AUTOSAR XML (schema 00049)
package /SwComponentTypes
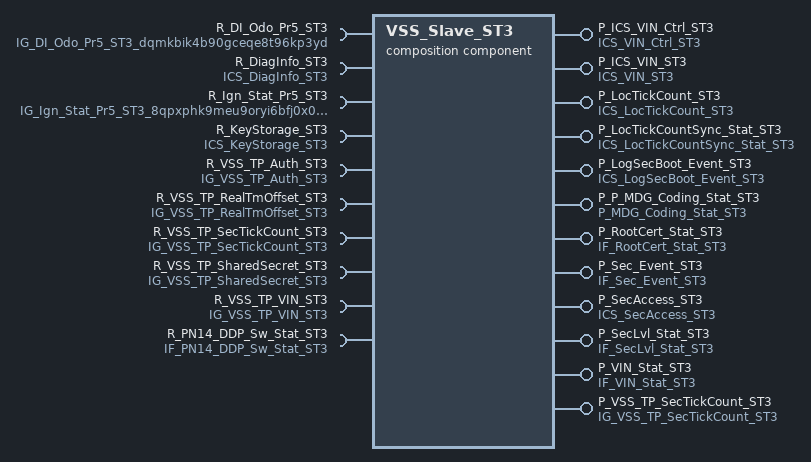
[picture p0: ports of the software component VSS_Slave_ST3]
  composition sw component type VSS_Slave_ST3  # Vehicle Security Slave
    11 x provide port:
      P_ICS_VIN_Ctrl_ST3: provided-com-specs=[{operation=Lock, queue-length=1}, {operation=Set, queue-length=1}], provided-interface=ICS_VIN_Ctrl_ST3  # Steuerung Fahrzeugidentifikationsnummer / Vehicle Identification Number control
      P_ICS_VIN_ST3: server-com-spec{operation=Get, queue-length=1}, provided-interface=ICS_VIN_ST3  # Fahrzeugidentifikationsnummer / Vehicle Identification Number
      P_LocTickCount_ST3: server-com-spec{operation=Get, queue-length=1}, provided-interface=ICS_LocTickCount_ST3  # Lokale Zeit / Local tick count
      P_LocTickCountSync_Stat_ST3: server-com-spec{operation=Get, queue-length=1}, provided-interface=ICS_LocTickCountSync_Stat_ST3  # Synchronisations-Status lokale Zeit / Local tick count synchronisation state
      P_LogSecBoot_Event_ST3: server-com-spec{operation=LogSecBootEvent, queue-length=1}, provided-interface=ICS_LogSecBoot_Event_ST3  # Security Boot-Ereignis aufzeichnen / Log security boot event
      P_P_MDG_Coding_Stat_ST3: mode-switch-sender-com-spec{mode-group=Coding_Status, queue-length=1}, provided-interface=P_MDG_Coding_Stat_ST3  # Kodierungs-Status / Coding state
      P_RootCert_Stat_ST3: nonqueued-sender-com-spec{data-element=isProductive, init-value=constant-reference=XDIS_h5tcyk98kzbgrc5svasomeyt}, provided-interface=IF_RootCert_Stat_ST3  # Status Root Certificate / Root certificate state
      P_Sec_Event_ST3: nonqueued-sender-com-spec{data-element=Data, init-value=constant-reference=XDIS_6146w3b2vgdunnu49c413rpbf}, provided-interface=IF_Sec_Event_ST3  # Security-Ereignis / Security event
      P_SecAccess_ST3: provided-com-specs=[{operation=CompareKey, queue-length=1}, {operation=GetSeed, queue-length=1}], provided-interface=ICS_SecAccess_ST3  # Security-Zugriff / Security access
      P_SecLvl_Stat_ST3: nonqueued-sender-com-spec{data-element=currentLevel, init-value=constant-reference=XDIS_2kt9ss9xytkqyzr4359iyexvi}, provided-interface=IF_SecLvl_Stat_ST3  # Status Security-Level / Security level state
      P_VIN_Stat_ST3: nonqueued-sender-com-spec{data-element=status, init-value=constant-reference=XDIS_e2iocagv39mx6wej6m836yqb3}, provided-interface=IF_VIN_Stat_ST3  # Status Fahrzeugidentifikationsnummer / Vehicle Indentification Number state
    9 x require port:
      R_DI_Odo_Pr5_ST3: nonqueued-receiver-com-spec{data-element=DI_Odo_Pr5_ST3, reception-props=timeout=0, end-to-end-transformation-com-spec-props=disable-end-to-end-check=true, init-value=constant-reference=XDIS_8ty18e89uj9dq1u10d39n5ao8}, required-interface=IG_DI_Odo_Pr5_ST3_dqmkbik4b90gceqe8t96kp3yd  # DriverInformation Odometer (degraded)
      R_DiagInfo_ST3: client-com-spec=Get, required-interface=ICS_DiagInfo_ST3  # Diagnose-Information / Diagnostic information
      R_Ign_Stat_Pr5_ST3: nonqueued-receiver-com-spec{data-element=Ign_Stat_Pr5_ST3, reception-props=timeout=0, end-to-end-transformation-com-spec-props=disable-end-to-end-check=true, init-value=constant-reference=XDIS_27u3muzqwjdvnos2w0sy90oxa}, required-interface=IG_Ign_Stat_Pr5_ST3_8qpxphk9meu9oryi6bfj0x04b  # Zuendungsstatus (degraded) / Ignition state (degraded)
      R_KeyStorage_ST3: client-com-spec=StorePermanently, required-interface=ICS_KeyStorage_ST3  # Schlüssel-Speicher / Key storage
      R_VSS_TP_Auth_ST3: nonqueued-receiver-com-spec{data-element=VSS_TP_Auth_ST3, reception-props=timeout=0, init-value=constant-reference=XDIS_12zcafvpuxi1hcqhklsbnv4pg}, required-interface=IG_VSS_TP_Auth_ST3  # VSS-Transportprotokoll für Authentifizierung / Vehicle Security System Transport Protocol for authentication broadcast
      R_VSS_TP_RealTmOffset_ST3: nonqueued-receiver-com-spec{data-element=VSS_TP_RealTmOffset_ST3, reception-props=timeout=0, init-value=constant-reference=XDIS_12zcafvpuxi1hcqhklsbnv4pg}, required-interface=IG_VSS_TP_RealTmOffset_ST3  # VSS-Transportprotokoll für Echtzeit-Offset / Vehicle Security System Transport Protocol for real time offset broadcast
      R_VSS_TP_SecTickCount_ST3: nonqueued-receiver-com-spec{data-element=VSS_TP_SecTickCount_ST3, reception-props=timeout=0, init-value=constant-reference=XDIS_12zcafvpuxi1hcqhklsbnv4pg}, required-interface=IG_VSS_TP_SecTickCount_ST3  # VSS-Transportprotokoll für sichere Zeit / Vehicle Security System Transport Protocol for secure tick count
      R_VSS_TP_SharedSecret_ST3: nonqueued-receiver-com-spec{data-element=VSS_TP_SharedSecret_ST3, reception-props=timeout=0, init-value=constant-reference=XDIS_12zcafvpuxi1hcqhklsbnv4pg}, required-interface=IG_VSS_TP_SharedSecret_ST3  # VSS-Transportprotokoll für gemeinsames Geheimnis / Vehicle Security System Transport Protocol for shared secret broadcast
      R_VSS_TP_VIN_ST3: nonqueued-receiver-com-spec{data-element=VSS_TP_VIN_ST3, reception-props=timeout=0, init-value=constant-reference=XDIS_3jcrrl3ll1e4yr6lszlogfin7}, required-interface=IG_VSS_TP_VIN_ST3  # VSS-Transportprotokoll für Fahrzeugidentifikationsnummer / Vehicle Security System Transport Protocol for Vehicle Identification Number
    provide port P_VSS_TP_SecTickCount_ST3: nonqueued-sender-com-spec{data-element=VSS_TP_SecTickCount_ST3, init-value=constant-reference=XDIS_12zcafvpuxi1hcqhklsbnv4pg}, provided-interface=IG_VSS_TP_SecTickCount_ST3
    require port R_PN14_DDP_Sw_Stat_ST3: nonqueued-receiver-com-spec{data-element=PN14_DDP_Sw_Stat_ST3, reception-props=timeout=0, init-value=constant-reference=XDIS_c8apwmaohcx1gxigvciebloy2}, required-interface=IF_PN14_DDP_Sw_Stat_ST3  # Schalterstatus Tiefentladeschutz / Deep discharge protection switch state
    6 x component:
      Ct_MBBL_SsaAppl_Coding: type=Ct_MBBL_SsaAppl_Coding
      Ct_MBBL_SsaAppl_General: type=Ct_MBBL_SsaAppl_General
      Ct_MBBL_SsaAppl_ProjectSpecific: type=Ct_MBBL_SsaAppl_ProjectSpecific
      Ct_MBBL_SsaAppl_TrustModel: type=Ct_MBBL_SsaAppl_TrustModel
      Ssa: type=Ssa
      Ct_ProjectInformation: type=Ct_ProjectInformation
    connect Ssa.P_ICS_SecAccess_ST3 -> Ct_MBBL_SsaAppl_ProjectSpecific.P_ICS_SecAccess_ST3
    connect Ssa.P_MDG_Coding_Stat_ST3 -> Ct_MBBL_SsaAppl_Coding.P_MDG_Coding_Stat_ST3
    connect Ct_MBBL_SsaAppl_General.R_ICS_DiagInfo_ST3 -> Ssa.R_ICS_DiagInfo_ST3
    connect Ct_MBBL_SsaAppl_General.R_ICS_KeyStorage_ST3 -> Ssa.R_ICS_KeyStorage_ST3
    delegate Ssa.R_VSS_TP_SecTickCount_ST3 <-> outer port R_VSS_TP_SecTickCount_ST3
    delegate Ssa.R_Ign_Stat_Pr5_ST3 <-> outer port R_Ign_Stat_Pr5_ST3
    delegate Ssa.R_VSS_TP_Auth_ST3 <-> outer port R_VSS_TP_Auth_ST3
    delegate Ssa.R_VSS_TP_RealTmOffset_ST3 <-> outer port R_VSS_TP_RealTmOffset_ST3
    delegate Ssa.R_VSS_TP_SharedSecret_ST3 <-> outer port R_VSS_TP_SharedSecret_ST3
    delegate Ssa.R_VSS_TP_VIN_ST3 <-> outer port R_VSS_TP_VIN_ST3
    delegate Ssa.P_ICS_VIN_Ctrl_ST3 <-> outer port P_ICS_VIN_Ctrl_ST3
    delegate Ssa.P_ICS_Sec_Event_ST3 <-> outer port P_Sec_Event_ST3
    delegate Ssa.P_IF_SecLvl_Stat_ST3 <-> outer port P_SecLvl_Stat_ST3
    delegate Ssa.P_MDG_Coding_Stat_ST3 <-> outer port P_P_MDG_Coding_Stat_ST3
    delegate Ssa.P_IF_RootCert_Stat_ST3 <-> outer port P_RootCert_Stat_ST3
    delegate Ssa.P_IF_VIN_Stat_ST3 <-> outer port P_VIN_Stat_ST3
    delegate Ssa.P_ICS_LocTickCountSync_Stat_ST3 <-> outer port P_LocTickCountSync_Stat_ST3
    delegate Ssa.P_ICS_VIN_ST3 <-> outer port P_ICS_VIN_ST3
    delegate Ssa.P_ICS_LocTickCount_ST3 <-> outer port P_LocTickCount_ST3
    connect Ct_ProjectInformation.Pp_InputFileVersions -> Ct_MBBL_SsaAppl_General.Pp_InputFileVersions
    delegate Ssa.R_Odo_Pr5_ST3 <-> outer port R_DI_Odo_Pr5_ST3
